# R7FA2T107 register map
Vendor: Renesas Electronics Corporation; Series: RA2; File version: 1.00.00
CPU: CM23 r1p0, little endian, MPU, no FPU, VTOR, 2 interrupt priority bits, 32 interrupts
Registers are 8-bit, read-write, reset 0x0 unless marked. A register's access mark holds for its fields unless they carry their own. Offsets are from the block's base; [hi:lo] are bit positions; lines under a group give offsets from that group; {n}, {i} and the like mark numbered series; 'fields as' and 'values as' point back to an identical list.

## GPT160 (part 1 of 2) — General PWM 16-bit Timer 0
Base 0x40089000
Same registers: GPT161 0x40089100, GPT162 0x40089200
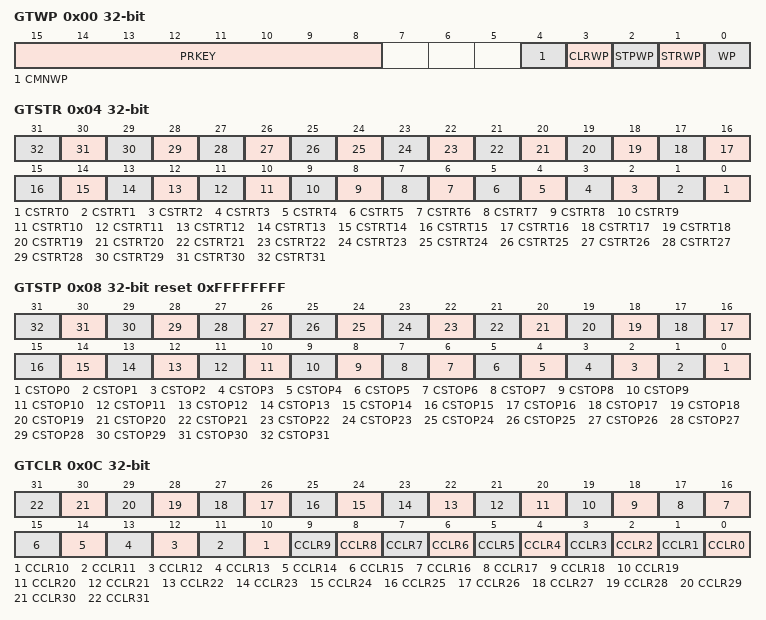
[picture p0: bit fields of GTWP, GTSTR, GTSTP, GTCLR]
0x00 GTWP 32-bit — General PWM Timer Write-Protection Register
  [15:8] PRKEY wo — GTWP Key Code
  [4] CMNWP — Common Register Write Disabled
    0=Write to the register is enabled; 1=Write to the register is disabled
  [3] CLRWP — GTCLR.CCLR Bit Write Disable
    0=Write to the bit is enabled; 1=Write to the bit is disabled
  [2] STPWP — GTSTP.CSTOP Bit Write Disable
    values as CLRWP
  [1] STRWP — GTSTR.CSTRT Bit Write Disable
    values as CLRWP
  [0] WP — Register Write Disable
    0=Write to the register enabled; 1=Write to the register disabled
0x04 GTSTR 32-bit — General PWM Timer Software Start Register
  [all] fields
    0=GTCNT counter is not started; 1=GTCNT counter is started
  [n] CSTRT{n} (n=0..31) — Channel n GTCNT Count Start (n is the same as the bit position value)
0x08 GTSTP 32-bit reset 0xFFFFFFFF — General PWM Timer Software Stop Register
  [all] fields
    0=GTCNT counter is not stopped; 1=GTCNT counter stopped
  [n] CSTOP{n} (n=0..31) — Channel n GTCNT Count Stop (n is the same as the bit position value)
0x0C GTCLR 32-bit wo — General PWM Timer Software Clear Register
  [all] fields
    0=GTCNT counter is not cleared; 1=GTCNT counter is cleared
  [n] CCLR{n} (n=0..31) — Channel n GTCNT Count Clear (n : the same as bit position value)
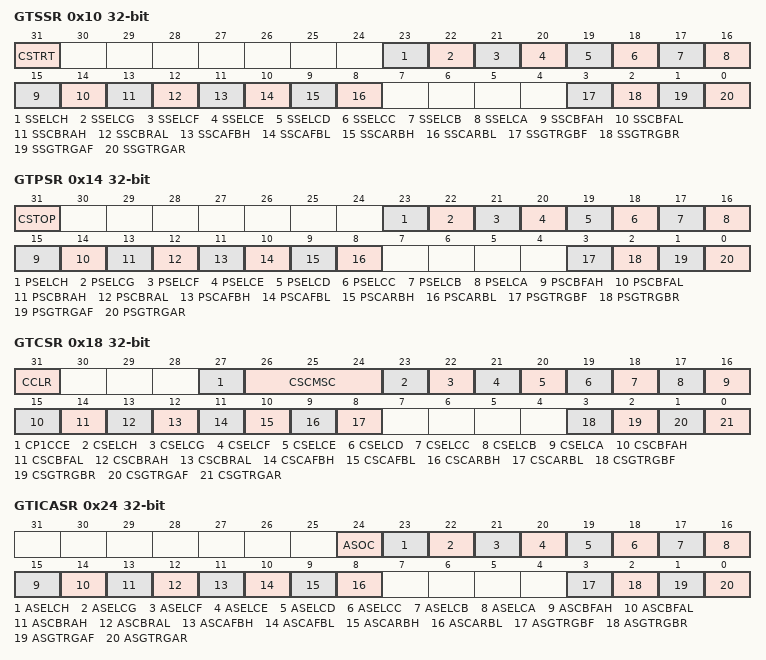
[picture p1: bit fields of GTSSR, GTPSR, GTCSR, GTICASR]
0x10 GTSSR 32-bit — General PWM Timer Start Source Select Register
  [31] CSTRT — Software Source Counter Start Enable
    0=Counter start disabled by the GTSTR register; 1=Counter start enabled by the GTSTR register
  [23] SSELCH — ELC_GPTH Event Source Counter Start Enable
    0=Counter start disabled at the ELC_GPTH input; 1=Counter start enabled at the ELC_GPTH input
  [22] SSELCG — ELC_GPTG Event Source Counter Start Enable
    0=Counter start disabled at the ELC_GPTG input; 1=Counter start enabled at the ELC_GPTG input
  [21] SSELCF — ELC_GPTF Event Source Counter Start Enable
    0=Counter start disabled at the ELC_GPTF input; 1=Counter start enabled at the ELC_GPTF input
  [20] SSELCE — ELC_GPTE Event Source Counter Start Enable
    0=Counter start disabled at the ELC_GPTE input; 1=Counter start enabled at the ELC_GPTE input
  [19] SSELCD — ELC_GPTD Event Source Counter Start Enable
    0=Counter start disabled at the ELC_GPTD input; 1=Counter start enabled at the ELC_GPTD input
  [18] SSELCC — ELC_GPTC Event Source Counter Start Enable
    0=Counter start disabled at the ELC_GPTC input; 1=Counter start enabled at the ELC_GPTC input
  [17] SSELCB — ELC_GPTB Event Source Counter Start Enable
    0=Counter start disabled at the ELC_GPTB input; 1=Counter start enabled at the ELC_GPTB input
  [16] SSELCA — ELC_GPTA Event Source Counter Start Enable
    0=Counter start disabled at the ELC_GPTA input; 1=Counter start enabled at the ELC_GPTA input
  [15] SSCBFAH — GTIOCnB Pin Falling Input during GTIOCnA Value High Source Counter Start Enable
    0=Counter start disabled on the falling edge of GTIOCnB input when GTIOCnA input is 1; 1=Counter start enabled on the falling edge of GTIOCnB input when GTIOCnA input is 1
  [14] SSCBFAL — GTIOCnB Pin Falling Input during GTIOCnA Value Low Source Counter Start Enable
    0=Counter start disabled on the falling edge of GTIOCnB input when GTIOCnA input is 0; 1=Counter start enabled on the falling edge of GTIOCnB input when GTIOCnA input is 0
  [13] SSCBRAH — GTIOCnB Pin Rising Input during GTIOCnA Value High Source Counter Start Enable
    0=Counter start disabled on the rising edge of GTIOCnB input when GTIOCnA input is 1; 1=Counter start enabled on the rising edge of GTIOCnB input when GTIOCnA input is 1
  [12] SSCBRAL — GTIOCnB Pin Rising Input during GTIOCnA Value Low Source Counter Start Enable
    0=Counter start disabled on the rising edge of GTIOCnB input when GTIOCnA input is 0; 1=Counter start enabled on the rising edge of GTIOCnB input when GTIOCnA input is 0
  [11] SSCAFBH — GTIOCnA Pin Falling Input during GTIOCnB Value High Source Counter Start Enable
    0=Counter start disabled on the falling edge of GTIOCnA input when GTIOCnB input is 1; 1=Counter start enabled on the falling edge of GTIOCnA input when GTIOCnB input is 1
  [10] SSCAFBL — GTIOCnA Pin Falling Input during GTIOCnB Value Low Source Counter Start Enable
    0=Counter start disabled on the falling edge of GTIOCnA input when GTIOCnB input is 0; 1=Counter start enabled on the falling edge of GTIOCnA input when GTIOCnB input is 0
  [9] SSCARBH — GTIOCnA Pin Rising Input during GTIOCnB Value High Source Counter Start Enable
    0=Counter start disabled on the rising edge of GTIOCnA input when GTIOCnB input is 1; 1=Counter start enabled on the rising edge of GTIOCnA input when GTIOCnB input is 1
  [8] SSCARBL — GTIOCnA Pin Rising Input during GTIOCnB Value Low Source Counter Start Enable
    0=Counter start disabled on the rising edge of GTIOCnA input when GTIOCnB input is 0; 1=Counter start enabled on the rising edge of GTIOCnA input when GTIOCnB input is 0
  [3] SSGTRGBF — GTETRGB Pin Falling Input Source Counter Start Enable
    0=Counter start disabled on the falling edge of GTETRGB input; 1=Counter start enabled on the falling edge of GTETRGB input
  [2] SSGTRGBR — GTETRGB Pin Rising Input Source Counter Start Enable
    0=Counter start disabled on the rising edge of GTETRGB input; 1=Counter start enabled on the rising edge of GTETRGB input
  [1] SSGTRGAF — GTETRGA Pin Falling Input Source Counter Start Enable
    0=Counter start disabled on the falling edge of GTETRGA input; 1=Counter start enabled on the falling edge of GTETRGA input
  [0] SSGTRGAR — GTETRGA Pin Rising Input Source Counter Start Enable
    0=Counter start disabled on the rising edge of GTETRGA input; 1=Counter start enabled on the rising edge of GTETRGA input
0x14 GTPSR 32-bit — General PWM Timer Stop Source Select Register
  [31] CSTOP — Software Source Counter Stop Enable
    0=Counter stop disabled by the GTSTP register; 1=Counter stop enabled by the GTSTP register
  [23] PSELCH — ELC_GPTH Event Source Counter Stop Enable
    0=Counter stop disabled at the ELC_GPTH input; 1=Counter stop enabled at the ELC_GPTH input
  [22] PSELCG — ELC_GPTG Event Source Counter Stop Enable
    0=Counter stop disabled at the ELC_GPTG input; 1=Counter stop enabled at the ELC_GPTG input
  [21] PSELCF — ELC_GPTF Event Source Counter Stop Enable
    0=Counter stop disabled at the ELC_GPTF input; 1=Counter stop enabled at the ELC_GPTF input
  [20] PSELCE — ELC_GPTE Event Source Counter Stop Enable
    0=Counter stop disabled at the ELC_GPTE input; 1=Counter stop enabled at the ELC_GPTE input
  [19] PSELCD — ELC_GPTD Event Source Counter Stop Enable
    0=Counter stop disabled at the ELC_GPTD input; 1=Counter stop enabled at the ELC_GPTD input
  [18] PSELCC — ELC_GPTC Event Source Counter Stop Enable
    0=Counter stop disabled at the ELC_GPTC input; 1=Counter stop enabled at the ELC_GPTC input
  [17] PSELCB — ELC_GPTB Event Source Counter Stop Enable
    0=Counter stop disabled at the ELC_GPTB input; 1=Counter stop enabled at the ELC_GPTB input
  [16] PSELCA — ELC_GPTA Event Source Counter Stop Enable
    0=Counter stop disabled at the ELC_GPTA input; 1=Counter stop enabled at the ELC_GPTA input
  [15] PSCBFAH — GTIOCnB Pin Falling Input during GTIOCnA Value High Source Counter Stop Enable
    0=Counter stop disabled on the falling edge of GTIOCnB input when GTIOCnA input is 1; 1=Counter stop enabled on the falling edge of GTIOCnB input when GTIOCnA input is 1
  [14] PSCBFAL — GTIOCnB Pin Falling Input during GTIOCnA Value Low Source Counter Stop Enable
    0=Counter stop disabled on the falling edge of GTIOCnB input when GTIOCnA input is 0; 1=Counter stop enabled on the falling edge of GTIOCnB input when GTIOCnA input is 0
  [13] PSCBRAH — GTIOCnB Pin Rising Input during GTIOCnA Value High Source Counter Stop Enable
    0=Counter stop disabled on the rising edge of GTIOCnB input when GTIOCnA input is 1; 1=Counter stop enabled on the rising edge of GTIOCnB input when GTIOCnA input is 1
  [12] PSCBRAL — GTIOCnB Pin Rising Input during GTIOCnA Value Low Source Counter Stop Enable
    0=Counter stop disabled on the rising edge of GTIOCnB input when GTIOCnA input is 0; 1=Counter stop enabled on the rising edge of GTIOCnB input when GTIOCnA input is 0
  [11] PSCAFBH — GTIOCnA Pin Falling Input during GTIOCnB Value High Source Counter Stop Enable
    0=Counter stop disabled on the falling edge of GTIOCnA input when GTIOCnB input is 1; 1=Counter stop enabled on the falling edge of GTIOCnA input when GTIOCnB input is 1
  [10] PSCAFBL — GTIOCnA Pin Falling Input during GTIOCnB Value Low Source Counter Stop Enable
    0=Counter stop disabled on the falling edge of GTIOCnA input when GTIOCnB input is 0; 1=Counter stop enabled on the falling edge of GTIOCnA input when GTIOCnB input is 0
  [9] PSCARBH — GTIOCnA Pin Rising Input during GTIOCnB Value High Source Counter Stop Enable
    0=Counter stop disabled on the rising edge of GTIOCnA input when GTIOCnB input is 1; 1=Counter stop enabled on the rising edge of GTIOCnA input when GTIOCnB input is 1
  [8] PSCARBL — GTIOCnA Pin Rising Input during GTIOCnB Value Low Source Counter Stop Enable
    0=Counter stop disabled on the rising edge of GTIOCnA input when GTIOCnB input is 0; 1=Counter stop enabled on the rising edge of GTIOCnA input when GTIOCnB input is 0
  [3] PSGTRGBF — GTETRGB Pin Falling Input Source Counter Stop Enable
    0=Counter stop disabled on the falling edge of GTETRGB input; 1=Counter stop enabled on the falling edge of GTETRGB input
  [2] PSGTRGBR — GTETRGB Pin Rising Input Source Counter Stop Enable
    0=Counter stop disabled on the rising edge of GTETRGB input; 1=Counter stop enabled on the rising edge of GTETRGB input
  [1] PSGTRGAF — GTETRGA Pin Falling Input Source Counter Stop Enable
    0=Counter stop disabled on the falling edge of GTETRGA input; 1=Counter stop enabled on the falling edge of GTETRGA input
  [0] PSGTRGAR — GTETRGA Pin Rising Input Source Counter Stop Enable
    0=Counter stop disabled on the rising edge of GTETRGA input; 1=Counter stop enabled on the rising edge of GTETRGA input
0x18 GTCSR 32-bit — General PWM Timer Clear Source Select Register
  [31] CCLR — Software Source Counter Clear Enable
    0=Counter clear disabled by the GTCLR register; 1=Counter clear enabled by the GTCLR register
  [27] CP1CCE — Complementary PWM Mode 1 Crest Source Counter Clear Enable
    0=Counter clear disabled at the crest of complementary PWM mode 1; 1=Counter clear enabled at the crest of complementary PWM mode 1
  [26:24] CSCMSC — Compare Match/Input Capture/Synchronous Counter Clearing Source Counter Clear Enable
    0=Counter clear disabled by Compare match/ Input capture/ Synchronous counter clearing group; 1=Counter clear enabled at the GTCCRA register compare match/ Input capture; 2=Counter clear enabled at the GTCCRB register compare match/ Input capture; 3=Counter clear enabled at the GTCCRC register compare match; 4=Counter clear enabled at the GTCCRD register compare match; 5=Counter clear enabled at the GTCCRE register compare match; 6=Counter clear enabled at the GTCCRF register compare match; 7=Counter clear enabled at the synchronous counter clearing group
  [23] CSELCH — ELC_GPTH Event Source Counter Clear Enable
    0=Counter clear disabled at the ELC_GPTH input; 1=Counter clear enabled at the ELC_GPTH input
  [22] CSELCG — ELC_GPTG Event Source Counter Clear Enable
    0=Counter clear disabled at the ELC_GPTG input; 1=Counter clear enabled at the ELC_GPTG input
  [21] CSELCF — ELC_GPTF Event Source Counter Clear Enable
    0=Counter clear disabled at the ELC_GPTF input; 1=Counter clear enabled at the ELC_GPTF input
  [20] CSELCE — ELC_GPTE Event Source Counter Clear Enable
    0=Counter clear disabled at the ELC_GPTE input; 1=Counter clear enabled at the ELC_GPTE input
  [19] CSELCD — ELC_GPTD Event Source Counter Clear Enable
    0=Counter clear disabled at the ELC_GPTD input; 1=Counter clear enabled at the ELC_GPTD input
  [18] CSELCC — ELC_GPTC Event Source Counter Clear Enable
    0=Counter clear disabled at the ELC_GPTC input; 1=Counter clear enabled at the ELC_GPTC input
  [17] CSELCB — ELC_GPTB Event Source Counter Clear Enable
    0=Counter clear disabled at the ELC_GPTB input; 1=Counter clear enabled at the ELC_GPTB input
  [16] CSELCA — ELC_GPTA Event Source Counter Clear Enable
    0=Counter clear disabled at the ELC_GPTA input; 1=Counter clear enabled at the ELC_GPTA input
  [15] CSCBFAH — GTIOCnB Pin Falling Input during GTIOCnA Value High Source Counter Clear Enable
    0=Counter clear disabled on the falling edge of GTIOCnB input when GTIOCnA input is 1; 1=Counter clear enabled on the falling edge of GTIOCnB input when GTIOCnA input is 1
  [14] CSCBFAL — GTIOCnB Pin Falling Input during GTIOCnA Value Low Source Counter Clear Enable
    0=Counter clear disabled on the falling edge of GTIOCnB input when GTIOCnA input is 0; 1=Counter clear enabled on the falling edge of GTIOCnB input when GTIOCnA input is 0
  [13] CSCBRAH — GTIOCnB Pin Rising Input during GTIOCnA Value High Source Counter Clear Enable
    0=Counter clear disabled on the rising edge of GTIOCnB input when GTIOCnA input is 1; 1=Counter clear enabled on the rising edge of GTIOCnB input when GTIOCnA input is 1
  [12] CSCBRAL — GTIOCnB Pin Rising Input during GTIOCnA Value Low Source Counter Clear Enable
    0=Counter clear disabled on the rising edge of GTIOCnB input when GTIOCnA input is 0; 1=Counter clear enabled on the rising edge of GTIOCnB input when GTIOCnA input is 0
  [11] CSCAFBH — GTIOCnA Pin Falling Input during GTIOCnB Value High Source Counter Clear Enable
    0=Counter clear disabled on the falling edge of GTIOCnA input when GTIOCnB input is 1; 1=Counter clear enabled on the falling edge of GTIOCnA input when GTIOCnB input is 1
  [10] CSCAFBL — GTIOCnA Pin Falling Input during GTIOCnB Value Low Source Counter Clear Enable
    0=Counter clear disabled on the falling edge of GTIOCnA input when GTIOCnB input is 0; 1=Counter clear enabled on the falling edge of GTIOCnA input when GTIOCnB input is 0
  [9] CSCARBH — GTIOCnA Pin Rising Input during GTIOCnB Value High Source Counter Clear Enable
    0=Counter clear disabled on the rising edge of GTIOCnA input when GTIOCnB input is 1; 1=Counter clear enabled on the rising edge of GTIOCnA input when GTIOCnB input is 1
  [8] CSCARBL — GTIOCnA Pin Rising Input during GTIOCnB Value Low Source Counter Clear Enable
    0=Counter clear disabled on the rising edge of GTIOCnA input when GTIOCnB input is 0; 1=Counter clear enabled on the rising edge of GTIOCnA input when GTIOCnB input is 0
  [3] CSGTRGBF — GTETRGB Pin Falling Input Source Counter Clear Enable
    0=Counter clear disabled on the falling edge of GTETRGB input; 1=Counter clear enabled on the falling edge of GTETRGB input
  [2] CSGTRGBR — GTETRGB Pin Rising Input Source Counter Clear Enable
    0=Disable counter clear on the rising edge of GTETRGB input; 1=Enable counter clear on the rising edge of GTETRGB input
  [1] CSGTRGAF — GTETRGA Pin Falling Input Source Counter Clear Enable
    0=Counter clear disabled on the falling edge of GTETRGA input; 1=Counter clear enabled on the falling edge of GTETRGA input
  [0] CSGTRGAR — GTETRGA Pin Rising Input Source Counter Clear Enable
    0=Counter clear disabled on the rising edge of GTETRGA input; 1=Counter clear enabled on the rising edge of GTETRGA input
0x24 GTICASR 32-bit — General PWM Timer Input Capture Source Select Register A
  [24] ASOC — Other channel Source GTCCRA Input Capture Enable
    0=Disables GTCCRA input capture by other channel factor; 1=Enables GTCCRA input capture by other channel factor
  [23] ASELCH — ELC_GPTH Event Source GTCCRA Input Capture Enable
    0=GTCCRA input capture disabled at the ELC_GPTH input; 1=GTCCRA input capture enabled at the ELC_GPTH input
  [22] ASELCG — ELC_GPTG Event Source GTCCRA Input Capture Enable
    0=GTCCRA input capture disabled at the ELC_GPTG input; 1=GTCCRA input capture enabled at the ELC_GPTG input
  [21] ASELCF — ELC_GPTF Event Source GTCCRA Input Capture Enable
    0=GTCCRA input capture disabled at the ELC_GPTF input; 1=GTCCRA input capture enabled at the ELC_GPTF input
  [20] ASELCE — ELC_GPTE Event Source GTCCRA Input Capture Enable
    0=GTCCRA input capture disabled at the ELC_GPTE input; 1=GTCCRA input capture enabled at the ELC_GPTE input
  [19] ASELCD — ELC_GPTD Event Source GTCCRA Input Capture Enable
    0=GTCCRA input capture disabled at the ELC_GPTD input; 1=GTCCRA input capture enabled at the ELC_GPTD input
  [18] ASELCC — ELC_GPTC Event Source GTCCRA Input Capture Enable
    0=GTCCRA input capture disabled at the ELC_GPTC input; 1=GTCCRA input capture enabled at the ELC_GPTC input
  [17] ASELCB — ELC_GPTB Event Source GTCCRA Input Capture Enable
    0=GTCCRA input capture disabled at the ELC_GPTB input; 1=GTCCRA input capture enabled at the ELC_GPTB input
  [16] ASELCA — ELC_GPTA Event Source GTCCRA Input Capture Enable
    0=GTCCRA input capture disabled at the ELC_GPTA input; 1=GTCCRA input capture enabled at the ELC_GPTA input
  [15] ASCBFAH — GTIOCnB Pin Falling Input during GTIOCnA Value High Source GTCCRA Input Capture Enable
    0=GTCCRA input capture disabled on the falling edge of GTIOCnB input when GTIOCnA input is 1; 1=GTCCRA input capture enabled on the falling edge of GTIOCnB input when GTIOCnA input is 1
  [14] ASCBFAL — GTIOCnB Pin Falling Input during GTIOCnA Value Low Source GTCCRA Input Capture Enable
    0=GTCCRA input capture disabled on the falling edge of GTIOCnB input when GTIOCnA input is 0; 1=GTCCRA input capture enabled on the falling edge of GTIOCnB input when GTIOCnA input is 0
  [13] ASCBRAH — GTIOCnB Pin Rising Input during GTIOCnA Value High Source GTCCRA Input Capture Enable
    0=GTCCRA input capture disabled on the rising edge of GTIOCnB input when GTIOCnA input is 1; 1=GTCCRA input capture enabled on the rising edge of GTIOCnB input when GTIOCnA input is 1
  [12] ASCBRAL — GTIOCnB Pin Rising Input during GTIOCnA Value Low Source GTCCRA Input Capture Enable
    0=GTCCRA input capture disabled on the rising edge of GTIOCnB input when GTIOCnA input is 0; 1=GTCCRA input capture enabled on the rising edge of GTIOCnB input when GTIOCnA input is 0
  [11] ASCAFBH — GTIOCnA Pin Falling Input during GTIOCnB Value High Source GTCCRA Input Capture Enable
    0=GTCCRA input capture disabled on the falling edge of GTIOCnA input when GTIOCnB input is 1; 1=GTCCRA input capture enabled on the falling edge of GTIOCnA input when GTIOCnB input is 1
  [10] ASCAFBL — GTIOCnA Pin Falling Input during GTIOCnB Value Low Source GTCCRA Input Capture Enable
    0=GTCCRA input capture disabled on the falling edge of GTIOCnA input when GTIOCnB input is 0; 1=GTCCRA input capture enabled on the falling edge of GTIOCnA input when GTIOCnB input is 0
  [9] ASCARBH — GTIOCnA Pin Rising Input during GTIOCnB Value High Source GTCCRA Input Capture Enable
    0=GTCCRA input capture disabled on the rising edge of GTIOCnA input when GTIOCnB input is 1; 1=GTCCRA input capture enabled on the rising edge of GTIOCnA input when GTIOCnB input is 1
  [8] ASCARBL — GTIOCnA Pin Rising Input during GTIOCnB Value Low Source GTCCRA Input Capture Enable
    0=GTCCRA input capture disabled on the rising edge of GTIOCnA input when GTIOCnB input is 0; 1=GTCCRA input capture enabled on the rising edge of GTIOCnA input when GTIOCnB input is 0
  [3] ASGTRGBF — GTETRGB Pin Falling Input Source GTCCRA Input Capture Enable
    0=GTCCRA input capture disabled on the falling edge of GTETRGB input; 1=GTCCRA input capture enabled on the falling edge of GTETRGB input
  [2] ASGTRGBR — GTETRGB Pin Rising Input Source GTCCRA Input Capture Enable
    0=GTCCRA input capture disabled on the rising edge of GTETRGB input; 1=GTCCRA input capture enabled on the rising edge of GTETRGB input
  [1] ASGTRGAF — GTETRGA Pin Falling Input Source GTCCRA Input Capture Enable
    0=GTCCRA input capture disabled on the falling edge of GTETRGA input; 1=GTCCRA input capture enabled on the falling edge of GTETRGA input
  [0] ASGTRGAR — GTETRGA Pin Rising Input Source GTCCRA Input Capture Enable
    0=GTCCRA input capture disabled on the rising edge of GTETRGA input; 1=GTCCRA input capture enabled on the rising edge of GTETRGA input
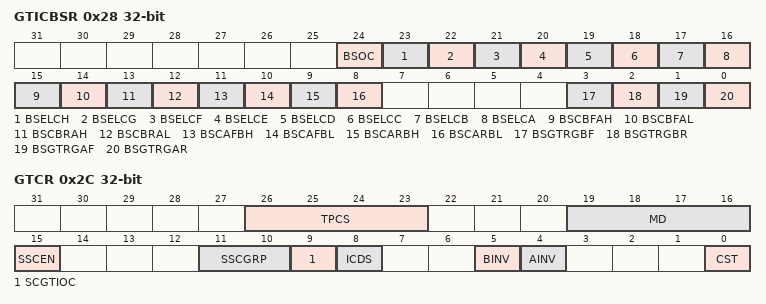
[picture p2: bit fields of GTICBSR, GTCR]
0x28 GTICBSR 32-bit — General PWM Timer Input Capture Source Select Register B
  [24] BSOC — Other Channel Source GTCCRB Input Capture Enable
    0=GTCCRB input capture disabled by other channel factor; 1=GTCCRB input capture enabled by other channel factor
  [23] BSELCH — ELC_GPTH Event Source GTCCRB Input Capture Enable
    0=GTCCRB input capture disabled at the ELC_GPTH input; 1=GTCCRB input capture enabled at the ELC_GPTH input
  [22] BSELCG — ELC_GPTG Event Source GTCCRB Input Capture Enable
    0=GTCCRB input capture disabled at the ELC_GPTG input; 1=GTCCRB input capture enabled at the ELC_GPTG input
  [21] BSELCF — ELC_GPTF Event Source GTCCRB Input Capture Enable
    0=GTCCRB input capture disabled at the ELC_GPTF input; 1=GTCCRB input capture enabled at the ELC_GPTF input
  [20] BSELCE — ELC_GPTE Event Source GTCCRB Input Capture Enable
    0=GTCCRB input capture disabled at the ELC_GPTE input; 1=GTCCRB input capture enabled at the ELC_GPTE input
  [19] BSELCD — ELC_GPTD Event Source GTCCRB Input Capture Enable
    0=GTCCRB input capture disabled at the ELC_GPTD input; 1=GTCCRB input capture enabled at the ELC_GPTD input
  [18] BSELCC — ELC_GPTC Event Source GTCCRB Input Capture Enable
    0=GTCCRB input capture disabled at the ELC_GPTC input; 1=GTCCRB input capture enabled at the ELC_GPTC input
  [17] BSELCB — ELC_GPTB Event Source GTCCRB Input Capture Enable
    0=GTCCRB input capture disabled at the ELC_GPTB input; 1=GTCCRB input capture enabled at the ELC_GPTB input
  [16] BSELCA — ELC_GPTA Event Source GTCCRB Input Capture Enable
    0=GTCCRB input capture disabled at the ELC_GPTA input; 1=GTCCRB input capture enabled at the ELC_GPTA input
  [15] BSCBFAH — GTIOCnB Pin Falling Input during GTIOCnA Value High Source GTCCRB Input Capture Enable
    0=GTCCRB input capture disabled on the falling edge of GTIOCnB input when GTIOCnA input is 1; 1=GTCCRB input capture enabled on the falling edge of GTIOCnB input when GTIOCnA input is 1
  [14] BSCBFAL — GTIOCnB Pin Falling Input during GTIOCnA Value Low Source GTCCRB Input Capture Enable
    0=GTCCRB input capture disabled on the falling edge of GTIOCnB input when GTIOCnA input is 0; 1=GTCCRB input capture enabled on the falling edge of GTIOCnB input when GTIOCnA input is 0
  [13] BSCBRAH — GTIOCnB Pin Rising Input during GTIOCnA Value High Source GTCCRB Input Capture Enable
    0=GTCCRB input capture disabled on the rising edge of GTIOCnB input when GTIOCnA input is 1; 1=GTCCRB input capture enabled on the rising edge of GTIOCnB input when GTIOCnA input is 1
  [12] BSCBRAL — GTIOCnB Pin Rising Input during GTIOCnA Value Low Source GTCCRB Input Capture Enable
    0=GTCCRB input capture disabled on the rising edge of GTIOCnB input when GTIOCnA input is 0; 1=GTCCRB input capture enabled on the rising edge of GTIOCnB input when GTIOCnA input is 0
  [11] BSCAFBH — GTIOCnA Pin Falling Input during GTIOCnB Value High Source GTCCRB Input Capture Enable
    0=GTCCRB input capture disabled on the falling edge of GTIOCnA input when GTIOCnB input is 1; 1=GTCCRB input capture enabled on the falling edge of GTIOCnA input when GTIOCnB input is 1
  [10] BSCAFBL — GTIOCnA Pin Falling Input during GTIOCnB Value Low Source GTCCRB Input Capture Enable
    0=GTCCRB input capture disabled on the falling edge of GTIOCnA input when GTIOCnB input is 0; 1=GTCCRB input capture enabled on the falling edge of GTIOCnA input when GTIOCnB input is 0
  [9] BSCARBH — GTIOCnA Pin Rising Input during GTIOCnB Value High Source GTCCRB Input Capture Enable
    0=GTCCRB input capture disabled on the rising edge of GTIOCnA input when GTIOCnB input is 1; 1=GTCCRB input capture enabled on the rising edge of GTIOCnA input when GTIOCnB input is 1
  [8] BSCARBL — GTIOCnA Pin Rising Input during GTIOCnB Value Low Source GTCCRB Input Capture Enable
    0=GTCCRB input capture disabled on the rising edge of GTIOCnA input when GTIOCnB input is 0; 1=GTCCRB input capture enabled on the rising edge of GTIOCnA input when GTIOCnB input is 0
  [3] BSGTRGBF — GTETRGB Pin Falling Input Source GTCCRB Input Capture Enable
    0=GTCCRB input capture disabled on the falling edge of GTETRGB input; 1=GTCCRB input capture enabled on the falling edge of GTETRGB input
  [2] BSGTRGBR — GTETRGB Pin Rising Input Source GTCCRB Input Capture Enable
    0=GTCCRB input capture disabled on the rising edge of GTETRGB input; 1=GTCCRB input capture enabled on the rising edge of GTETRGB input
  [1] BSGTRGAF — GTETRGA Pin Falling Input Source GTCCRB Input Capture Enable
    0=GTCCRB input capture disabled on the falling edge of GTETRGA input; 1=GTCCRB input capture enabled on the falling edge of GTETRGA input
  [0] BSGTRGAR — GTETRGA Pin Rising Input Source GTCCRB Input Capture Enable
    0=GTCCRB input capture disabled on the rising edge of GTETRGA input; 1=GTCCRB input capture enabled on the rising edge of GTETRGA input
0x2C GTCR 32-bit — General PWM Timer Control Register
  [26:23] TPCS — Timer Prescaler Select
    0=GTCLK/1; 1=GTCLK/2; 2=GTCLK/4; 3=GTCLK/8; 4=GTCLK/16; 5=GTCLK/32; 6=GTCLK/64; 8=GTCLK/256; 10=GTCLK/1024; 12=GTETRGA (through the POEG); 13=GTETRGB (through the POEG); other=Others (Setting prohibitedPOEG接続数に応じた、GTETRGA-D表示制御必要。)
  [19:16] MD — Mode Select
    0=Saw-wave PWM mode 1 (single buffer or double buffer possible); 1=Saw-wave one-shot pulse mode (fixed buffer operation); 2=Saw-wave PWM mode 2 (single buffer or double buffer possible); 4=Triangle-wave PWM mode 1 (32-bit transfer at trough) (single buffer or double buffer possible); 5=Triangle-wave PWM mode 2 (32-bit transfer at crest and trough) (single buffer or double buffer possible); 6=Triangle-wave PWM mode 3 (64-bit transfer at trough) (fixed buffer operation); 12=Complementary PWM mode 1 (transfer at crest); 13=Complementary PWM mode 2 (transfer at trough); 14=Complementary PWM mode 3 (transfer at crest and trough); 15=Complementary PWM mode 4 (immediate transfer); other=Others (Setting prohibited)
  [15] SSCEN — Synchronous Set/Clear Enable
    0=Disables synchronous set/clear of the GTCNT counter; 1=Enables synchronous set/clear of the GTCNT counter
  [11:10] SSCGRP — Synchronous Set/Clear Group Select
    0=Selects synchronous set/clear group A; 1=Selects synchronous set/clear group B; 2=Selects synchronous set/clear group C; 3=Selects synchronous set/clear group D
  [9] SCGTIOC — GTIOC Input Source Synchronous Clear Enable
    0=Disables the use of counter clear by GTIOC input as the clear factor for other channels; 1=Enables the use of counter clear by GTIOC input as the clear factor for other channels
  [8] ICDS — Input Capture Operation Select During Count Stop
    0=Input capture is operated during count stop; 1=Input capture is not operated during count stop
  [5] BINV — GTIOCnB input/output pin polarity reversal control
    0=Not invert; 1=Invert
  [4] AINV — GTIOCnA input/output pin polarity reversal control
    0=Not invert; 1=Invert
  [0] CST — Count Start
    0=Count operation is stopped; 1=Count operation is performed

## GPT163 (part 1 of 2) — General PWM 16-bit Timer 3
Base 0x40089300
Registers as GPT160; these are added or differ:
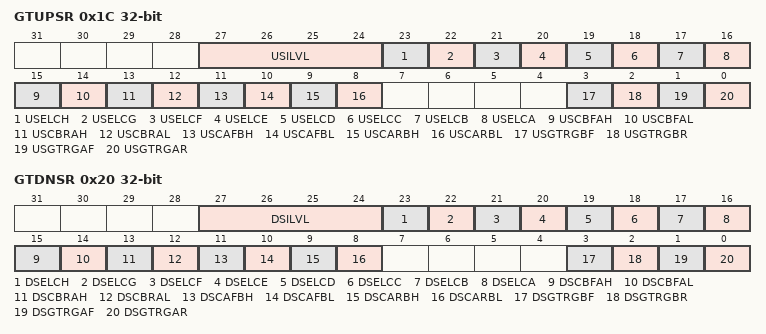
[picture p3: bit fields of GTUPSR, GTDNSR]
0x1C GTUPSR 32-bit — General PWM Timer Up Count Source Select Register
  [27:24] USILVL — External Input Level Source Count-Up Enable
    0=Disables count-up by external input level; 2=Enables count-up by GTIOCnA pin input level 0; 3=Enables count-up by GTIOCnA pin input level 1; 4=Enables count-up by GTIOCnB pin input level 0; 5=Enables count-up by GTIOCnB pin input level 1; 8=Enables count-up by GTETRGA pin input level 0; 9=Enables count-up by GTETRGA pin input level 1; 10=Enables count-up by GTETRGB pin input level 0; 11=Enables count-up by GTETRGB pin input level 1; other=Others (Setting prohibited)
  [23] USELCH — ELC_GPTH Event Source Counter Count Up Enable
    0=Counter count up disabled at the ELC_GPTH input; 1=Counter count up enabled at the ELC_GPTH input
  [22] USELCG — ELC_GPTG Event Source Counter Count Up Enable
    0=Counter count up disabled at the ELC_GPTG input; 1=Counter count up enabled at the ELC_GPTG input
  [21] USELCF — ELC_GPTF Event Source Counter Count Up Enable
    0=Counter count up disabled at the ELC_GPTF input; 1=Counter count up enabled at the ELC_GPTF input
  [20] USELCE — ELC_GPTE Event Source Counter Count Up Enable
    0=Counter count up disabled at the ELC_GPTE input; 1=Counter count up enabled at the ELC_GPTE input
  [19] USELCD — ELC_GPTD Event Source Counter Count Up Enable
    0=Counter count up disabled at the ELC_GPTD input; 1=Counter count up enabled at the ELC_GPTD input
  [18] USELCC — ELC_GPTC Event Source Counter Count Up Enable
    0=Counter count up disabled at the ELC_GPTC input; 1=Counter count up enabled at the ELC_GPTC input
  [17] USELCB — ELC_GPTB Event Source Counter Count Up Enable
    0=Counter count up disabled at the ELC_GPTB input; 1=Counter count up enabled at the ELC_GPTB input
  [16] USELCA — ELC_GPTA Event Source Counter Count Up Enable
    0=Counter count up disabled at the ELC_GPTA input; 1=Counter count up enabled at the ELC_GPTA input
  [15] USCBFAH — GTIOCnB Pin Falling Input during GTIOCnA Value High Source Counter Count Up Enable
    0=Counter count up disabled on the falling edge of GTIOCnB input when GTIOCnA input is 1; 1=Counter count up enabled on the falling edge of GTIOCnB input when GTIOCnA input is 1
  [14] USCBFAL — GTIOCnB Pin Falling Input during GTIOCnA Value Low Source Counter Count Up Enable
    0=Counter count up disabled on the falling edge of GTIOCnB input when GTIOCnA input is 0; 1=Counter count up enabled on the falling edge of GTIOCnB input when GTIOCnA input is 0
  [13] USCBRAH — GTIOCnB Pin Rising Input during GTIOCnA Value High Source Counter Count Up Enable
    0=Counter count up disabled on the rising edge of GTIOCnB input when GTIOCnA input is 1; 1=Counter count up enabled on the rising edge of GTIOCnB input when GTIOCnA input is 1
  [12] USCBRAL — GTIOCnB Pin Rising Input during GTIOCnA Value Low Source Counter Count Up Enable
    0=Counter count up disabled on the rising edge of GTIOCnB input when GTIOCnA input is 0; 1=Counter count up enabled on the rising edge of GTIOCnB input when GTIOCnA input is 0
  [11] USCAFBH — GTIOCnA Pin Falling Input during GTIOCnB Value High Source Counter Count Up Enable
    0=Counter count up disabled on the falling edge of GTIOCnA input when GTIOCnB input is 1; 1=Counter count up enabled on the falling edge of GTIOCnA input when GTIOCnB input is 1
  [10] USCAFBL — GTIOCnA Pin Falling Input during GTIOCnB Value Low Source Counter Count Up Enable
    0=Counter count up disabled on the falling edge of GTIOCnA input when GTIOCnB input is 0; 1=Counter count up enabled on the falling edge of GTIOCnA input when GTIOCnB input is 0
  [9] USCARBH — GTIOCnA Pin Rising Input during GTIOCnB Value High Source Counter Count Up Enable
    0=Counter count up disabled on the rising edge of GTIOCnA input when GTIOCnB input is 1; 1=Counter count up enabled on the rising edge of GTIOCnA input when GTIOCnB input is 1
  [8] USCARBL — GTIOCnA Pin Rising Input during GTIOCnB Value Low Source Counter Count Up Enable
    0=Counter count up disabled on the rising edge of GTIOCnA input when GTIOCnB input is 0; 1=Counter count up enabled on the rising edge of GTIOCnA input when GTIOCnB input is 0
  [3] USGTRGBF — GTETRGB Pin Falling Input Source Counter Count Up Enable
    0=Counter count up disabled on the falling edge of GTETRGB input; 1=Counter count up enabled on the falling edge of GTETRGB input
  [2] USGTRGBR — GTETRGB Pin Rising Input Source Counter Count Up Enable
    0=Counter count up disabled on the rising edge of GTETRGB input; 1=Counter count up enabled on the rising edge of GTETRGB input
  [1] USGTRGAF — GTETRGA Pin Falling Input Source Counter Count Up Enable
    0=Counter count up disabled on the falling edge of GTETRGA input; 1=Counter count up enabled on the falling edge of GTETRGA input
  [0] USGTRGAR — GTETRGA Pin Rising Input Source Counter Count Up Enable
    0=Counter count up disabled on the rising edge of GTETRGA input; 1=Counter count up enabled on the rising edge of GTETRGA input
0x20 GTDNSR 32-bit — General PWM Timer Down Count Source Select Register
  [27:24] DSILVL — External Input Level Source Count-Down Enable
    0=Disables count-down by external input level; 2=Enables count-down by GTIOCnA pin input level 0; 3=Enables count-down by GTIOCnA pin input level 1; 4=Enables count-down by GTIOCnB pin input level 0; 5=Enables count-down by GTIOCnB pin input level 1; 8=Enables count-down by GTETRGA pin input level 0; 9=Enables count-down by GTETRGA pin input level 1; 10=Enables count-down by GTETRGB pin input level 0; 11=Enables count-down by GTETRGB pin input level 1; other=Others (Setting prohibited)
  [23] DSELCH — ELC_GPTH Event Source Counter Count Down Enable
    0=Counter count down disabled at the ELC_GPTH input; 1=Counter count down enabled at the ELC_GPTH input
  [22] DSELCG — ELC_GPTG Event Source Counter Count Down Enable
    0=Counter count down disabled at the ELC_GPTG input; 1=Counter count down enabled at the ELC_GPTG input
  [21] DSELCF — ELC_GPTF Event Source Counter Count Down Enable
    0=Counter count down disabled at the ELC_GPTF input; 1=Counter count down enabled at the ELC_GPTF input
  [20] DSELCE — ELC_GPTE Event Source Counter Count Down Enable
    0=Counter count down disabled at the ELC_GPTE input; 1=Counter count down enabled at the ELC_GPTE input
  [19] DSELCD — ELC_GPTD Event Source Counter Count Down Enable
    0=Counter count down disabled at the ELC_GPTD input; 1=Counter count down enabled at the ELC_GPTD input
  [18] DSELCC — ELC_GPTC Event Source Counter Count Down Enable
    0=Counter count down disabled at the ELC_GPTC input; 1=Counter count down enabled at the ELC_GPTC input
  [17] DSELCB — ELC_GPTB Event Source Counter Count Down Enable
    0=Counter count down disabled at the ELC_GPTB input; 1=Counter count down enabled at the ELC_GPTB input
  [16] DSELCA — ELC_GPTA Event Source Counter Count Down Enable
    0=Counter count down disabled at the ELC_GPTA input; 1=Counter count down enabled at the ELC_GPTA input
  [15] DSCBFAH — GTIOCnB Pin Falling Input during GTIOCnA Value High Source Counter Count Down Enable
    0=Counter count down disabled on the falling edge of GTIOCnB input when GTIOCnA input is 1; 1=Counter count down enabled on the falling edge of GTIOCnB input when GTIOCnA input is 1
  [14] DSCBFAL — GTIOCnB Pin Falling Input during GTIOCnA Value Low Source Counter Count Down Enable
    0=Counter count down disabled on the falling edge of GTIOCnB input when GTIOCnA input is 0; 1=Counter count down enabled on the falling edge of GTIOCnB input when GTIOCnA input is 0
  [13] DSCBRAH — GTIOCnB Pin Rising Input during GTIOCnA Value High Source Counter Count Down Enable
    0=Counter count down disabled on the rising edge of GTIOCnB input when GTIOCnA input is 1; 1=Counter count down enabled on the rising edge of GTIOCnB input when GTIOCnA input is 1
  [12] DSCBRAL — GTIOCnB Pin Rising Input during GTIOCnA Value Low Source Counter Count Down Enable
    0=Counter count down disabled on the rising edge of GTIOCnB input when GTIOCnA input is 0; 1=Counter count down enabled on the rising edge of GTIOCnB input when GTIOCnA input is 0
  [11] DSCAFBH — GTIOCnA Pin Falling Input during GTIOCnB Value High Source Counter Count Down Enable
    0=Counter count down disabled on the falling edge of GTIOCnA input when GTIOCnB input is 1; 1=Counter count down enabled on the falling edge of GTIOCnA input when GTIOCnB input is 1
  [10] DSCAFBL — GTIOCnA Pin Falling Input during GTIOCnB Value Low Source Counter Count Down Enable
    0=Counter count down disabled on the falling edge of GTIOCnA input when GTIOCnB input is 0; 1=Counter count down enabled on the falling edge of GTIOCnA input when GTIOCnB input is 0
  [9] DSCARBH — GTIOCnA Pin Rising Input during GTIOCnB Value High Source Counter Count Down Enable
    0=Counter count down disabled on the rising edge of GTIOCnA input when GTIOCnB input is 1; 1=Counter count down enabled on the rising edge of GTIOCnA input when GTIOCnB input is 1
  [8] DSCARBL — GTIOCnA Pin Rising Input during GTIOCnB Value Low Source Counter Count Down Enable
    0=Counter count down disabled on the rising edge of GTIOCnA input when GTIOCnB input is 0; 1=Counter count down enabled on the rising edge of GTIOCnA input when GTIOCnB input is 0
  [3] DSGTRGBF — GTETRGB Pin Falling Input Source Counter Count Down Enable
    0=Counter count down disabled on the falling edge of GTETRGB input; 1=Counter count down enabled on the falling edge of GTETRGB input
  [2] DSGTRGBR — GTETRGB Pin Rising Input Source Counter Count Down Enable
    0=Counter count down disabled on the rising edge of GTETRGB input; 1=Counter count down enabled on the rising edge of GTETRGB input
  [1] DSGTRGAF — GTETRGA Pin Falling Input Source Counter Count Down Enable
    0=Counter count down disabled on the falling edge of GTETRGA input; 1=Counter count down enabled on the falling edge of GTETRGA input
  [0] DSGTRGAR — GTETRGA Pin Rising Input Source Counter Count Down Enable
    0=Counter count down disabled on the rising edge of GTETRGA input; 1=Counter count down enabled on the rising edge of GTETRGA input
